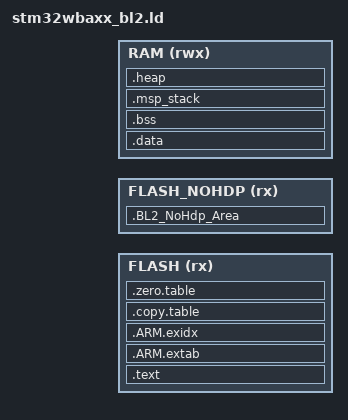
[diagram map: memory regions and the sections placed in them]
/*
******************************************************************************
**
** @file        : LinkerScript.ld
**
** @author      : Auto-generated by STM32CubeIDE
**
** @brief       : Linker script for STM32WBAxx Device from STM32WBA series
**
**                Set heap size, stack size and stack location according
**                to application requirements.
**
**                Set memory bank area and size if external memory is used
**
**  Target      : STMicroelectronics STM32
**
**  Distribution: The file is distributed as is, without any warranty
**                of any kind.
**
******************************************************************************
** @attention
**
** Copyright (c) 2024 STMicroelectronics.
** All rights reserved.
**
** This software is licensed under terms that can be found in the LICENSE file
** in the root directory of this software component.
** If no LICENSE file comes with this software, it is provided AS-IS.
**
******************************************************************************
*/
#include "region_defs.h"

/* Entry Point */
ENTRY(Reset_Handler)

/* Highest address of the user mode stack */
_estack = ORIGIN(RAM) + LENGTH(RAM); /* end of "RAM" Ram type memory */

_Min_Heap_Size  = BL2_HEAP_SIZE;
_Min_Stack_Size = BL2_MSP_STACK_SIZE;

/* Memories definition */
MEMORY
{
  FLASH (rx)  : ORIGIN = BL2_CODE_START, LENGTH = BL2_CODE_SIZE
  FLASH_NOHDP (rx)  : ORIGIN = BL2_NOHDP_CODE_START, LENGTH = BL2_NOHDP_CODE_SIZE
  RAM   (rwx) : ORIGIN = BL2_DATA_START, LENGTH = BL2_DATA_SIZE
}

/* Library configurations */
GROUP(libgcc.a libc.a libm.a libnosys.a)

/* Sections */
SECTIONS
{
  .BL2_NoHdp_Area :
  {
    KEEP(*(.BL2_NoHdp_Data))
    KEEP(*(.BL2_NoHdp_Code))
    *mpu_armv8m_drv.o (.text* .rodata*)
    KEEP(*(.BL2_Error_Code))
    __hdp_end__ = .;
  } > FLASH_NOHDP

  /* The program code and other data into "FLASH" Rom type memory */
  .text (BL2_CODE_START):
  {
    KEEP(*(.vectors))
    __Vectors_End = .;
    __Vectors_Size = __Vectors_End - __Vectors;
    __end__ = .;

    *(.text*)

    KEEP(*(.init))
    KEEP(*(.fini))

    /* .ctors */
    *crtbegin.o(.ctors)
    *crtbegin?.o(.ctors)
    *(EXCLUDE_FILE(*crtend?.o *crtend.o) .ctors)
    *(SORT(.ctors.*))
    *(.ctors)

    /* .dtors */
    *crtbegin.o(.dtors)
    *crtbegin?.o(.dtors)
    *(EXCLUDE_FILE(*crtend?.o *crtend.o) .dtors)
    *(SORT(.dtors.*))
    *(.dtors)

    *(.rodata*)

    KEEP(*(.eh_frame*))
  } > FLASH

  .ARM.extab (READONLY) : /* The READONLY keyword is only supported in GCC11 and later, remove it if using GCC10 or earlier. */
  {
    *(.ARM.extab* .gnu.linkonce.armextab.*)
  } > FLASH

  __exidx_start = .;
  .ARM.exidx (READONLY) : /* The READONLY keyword is only supported in GCC11 and later, remove it if using GCC10 or earlier. */
  {
    *(.ARM.exidx* .gnu.linkonce.armexidx.*)
  } > FLASH
  __exidx_end = .;

  .copy.table (READONLY) : /* The READONLY keyword is only supported in GCC11 and later, remove it if using GCC10 or earlier. */
  {
    . = ALIGN(4);
    __copy_table_start__ = .;
    LONG (__etext)
    LONG (__data_start__)
    LONG ((__data_end__ - __data_start__)/4)
    __copy_table_end__ = .;
  } > FLASH

  .zero.table (READONLY) : /* The READONLY keyword is only supported in GCC11 and later, remove it if using GCC10 or earlier. */
  {
    . = ALIGN(4);
    __zero_table_start__ = .;
    LONG (__bss_start__)
    LONG ((__bss_end__ - __bss_start__)/4)
    __zero_table_end__ = .;
  } > FLASH

  __etext = .;

  .data : AT (__etext)
  {
    __data_start__ = .;
    *(vtable)
    *(.data*)

    . = ALIGN(4);
    /* preinit data */
    PROVIDE_HIDDEN (__preinit_array_start = .);
    KEEP(*(.preinit_array))
    PROVIDE_HIDDEN (__preinit_array_end = .);

    . = ALIGN(4);
    /* init data */
    PROVIDE_HIDDEN (__init_array_start = .);
    KEEP(*(SORT(.init_array.*)))
    KEEP(*(.init_array))
    PROVIDE_HIDDEN (__init_array_end = .);

    . = ALIGN(4);
    /* finit data */
    PROVIDE_HIDDEN (__fini_array_start = .);
    KEEP(*(SORT(.fini_array.*)))
    KEEP(*(.fini_array))
    PROVIDE_HIDDEN (__fini_array_end = .);

    KEEP(*(.jcr*))
    . = ALIGN(4);
    /* All data end */
    __data_end__ = .;

  } > RAM
  Image$$ER_CODE$$Base = __Vectors ;
  Image$$HDP_CODE$$Limit = __hdp_end__;
  .bss :
  {
    . = ALIGN(4);
    __bss_start__ = .;
    *(.bss*)
    *(COMMON)
    . = ALIGN(4);
    __bss_end__ = .;
  } > RAM

  bss_size = __bss_end__ - __bss_start__;

  .msp_stack :
  {
    . = ALIGN(8);
    KEEP(*(.psp_stack*))
    . += _Min_Stack_Size;
  } > RAM
  Image$$ARM_LIB_STACK$$ZI$$Limit = ADDR(.msp_stack) + SIZEOF(.msp_stack);
  Image$$ARM_LIB_STACK$$ZI$$Base = ADDR(.msp_stack) ;

  .heap :
  {
    . = ALIGN(8);
    __end__ = .;
    PROVIDE(end = .);
    __HeapBase = .;
    . += _Min_Heap_Size;
    __HeapLimit = .;
    __heap_limit = .; /* Add for _sbrk */
  } > RAM

  PROVIDE(__stack = Image$$ARM_LIB_STACK$$ZI$$Limit);
  PROVIDE(__StackTop = Image$$ARM_LIB_STACK$$ZI$$Limit);
  PROVIDE(__StackLimit = Image$$ARM_LIB_STACK$$ZI$$Base);
}
